# SIM3C164_B register map
File version: 1
CPU: 
Registers are 32-bit, read-write, reset 0x0 unless marked. A register's access mark holds for its fields unless they carry their own. Offsets are from the block's base; [hi:lo] are bit positions; {n}, {i} and the like mark numbered series.

## EXTVREG_0
Base 0x40042000
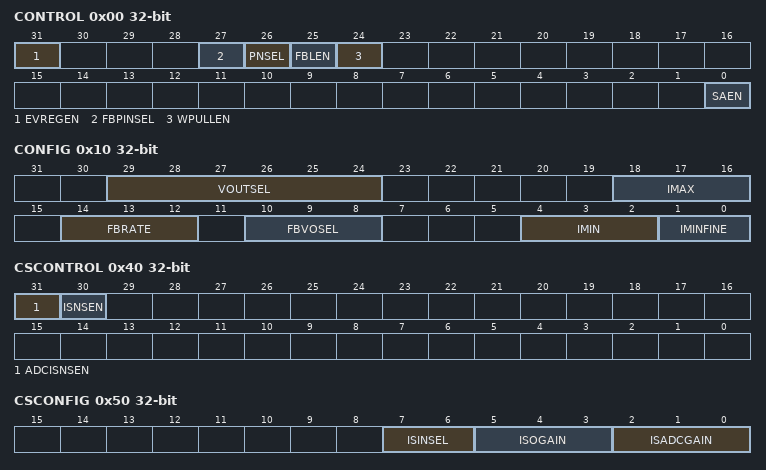
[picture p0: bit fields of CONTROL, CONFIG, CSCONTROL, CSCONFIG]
0x00 CONTROL — Module Control
  [31] EVREGEN — External Regulator Enable.
    0=DISABLED (Disable the external regulator.); 1=ENABLED (Enable the external regulator.)
  [27] FBPINSEL — Foldback Sensing Pin Select.
    0=EXREGSN (Use the input to the EXREGSN pin for foldback limiting.); 1=VREGIN (Use the input to the VREGIN pin for foldback limiting.)
  [26] PNSEL — NPN/PNP Type Select.
    0=NPN (Select NPN Mode.); 1=PNP (Select PNP Mode.)
  [25] FBLEN — Foldback Limiting Enable.
    0=DISABLED (Disable foldback limiting.); 1=ENABLED (Enable foldback limiting.)
  [24] WPULLEN — Weak Pull Up/Down Enable.
    0=DISABLED (Disable the external regulator weak pull-up/down resistor on the EXREGBD pin and weak pull-down resistor on the EXREGOUT pin.); 1=ENABLED (Enable the external regulator weak pull-up/down resistor on the EXREGBD pin and weak pull-down resistor on the EXREGOUT pin.)
  [0] SAEN — Stand-Alone Mode Enable.
    0=DISABLED (Use the external regulator in normal mode.); 1=ENABLED (Use the external regulator in stand-alone mode.)
0x10 CONFIG — Module Configuration
  [29:24] VOUTSEL — Regulator Output Voltage Select.
  [18:16] IMAX — Maximum Current Select.
    {v}={v+2}_UA (Maximum current limit is {v+2} uA.) (v=0..7)
  [14:12] FBRATE — Voltage Sense Gain Multiplier.
    0=4_UA_PER_V (Set the foldback rate to 4 uA/V.); 1=2_UA_PER_V (Set the foldback rate to 2 uA/V.); 2=1_UA_PER_V (Set the foldback rate to 1 uA/V.); 3=0P5_UA_PER_V (Set the foldback rate to 0.5 uA/V.); 5=8_UA_PER_V (Set the foldback rate to 8 uA/V.); 6=16_UA_PER_V (Set the foldback rate to 16 uA/V.); 7=32_UA_PER_V (Set the foldback rate to 32 uA/V.)
  [10:8] FBVOSEL — Foldback Voltage Offset Select.
    0=0_V (Foldback voltage offset is 0 V.); 1=0P5_V (Foldback voltage offset is 0.5 V.); 2=1_V (Foldback voltage offset is 1 V.); 3=1P5_V (Foldback voltage offset is 1.5 V.); 4=2_V (Foldback voltage offset is 2 V.); 5=2P5_V (Foldback voltage offset is 2.5 V.); 6=3_V (Foldback voltage offset is 3 V.); 7=3P5_V (Foldback voltage offset is 3.5 V.)
  [4:2] IMIN — Minimum Current Select.
    {v}={v+1}_UA (Minimum current limit is {v+1} uA + IMINFINE current.) (v=0..7)
  [1:0] IMINFINE — Minimum Current Fine Select.
    0=0_UA (Minimum current limit is IMIN current + 0 uA.); 1=0P25_UA (Minimum current limit is IMIN current + 0.25 uA.); 2=0P5_UA (Minimum current limit is IMIN current + 0.50 uA.); 3=0P75_UA (Minimum current limit is IMIN current + 0.75 uA.)
0x20 STATUS — Module Status
  [0] FBMAXF ro — Maximum Foldback Flag.
    0=NOT_SET (Maximum foldback has not been reached.); 1=SET (Maximum foldback has been reached.)
0x40 CSCONTROL — Current Sense Control
  [31] ADCISNSEN — ADC Current Sense Enable.
    0=DISABLED (Disable ADC current sensing.); 1=ENABLED (Enable ADC current sensing.)
  [30] ISNSEN — External Regulator Current Sense Enable.
    0=DISABLED (Disable external regulator current sensing.); 1=ENABLED (Enable external regulator current sensing.)
0x50 CSCONFIG — Current Sense Configuration
  [7:6] ISINSEL — External Regulator Current Sense Input Select.
    0=MODE0 (Select external regulator current sensing mode 0.); 1=MODE1 (Select external regulator current sensing mode 1.); 2=MODE2 (Select external regulator current sensing mode 2.)
  [5:3] ISOGAIN — External Regulator Current Sense Gain.
    0=16X (External regulator current sensing gain is 16.); 1=8X (External regulator current sensing gain is 8.); 2=4X (External regulator current sensing gain is 4.); 3=2X (External regulator current sensing gain is 2.); 4=External regulator current sensing gain is 1
  [2:0] ISADCGAIN — ADC Current Sense Gain.
    0=16X (ADC current sensing input gain is 16.); 1=8X (ADC current sensing input gain is 8.); 2=4X (ADC current sensing input gain is 4.); 3=2X (ADC current sensing input gain is 2.); 4=ADC current sensing input gain is 1
